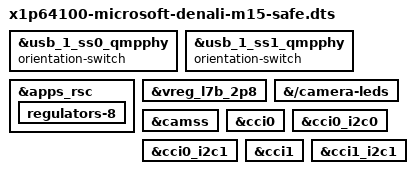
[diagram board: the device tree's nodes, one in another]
// SPDX-License-Identifier: BSD-3-Clause
/*
 * M15 fallback / safe mode (no GPU): complete functional system with
 * audio (speakers with D26 open-loop protection, microphones, DisplayPort audio),
 * cameras (rear OV13858 and front IMX681, RGB only; the unbound IR VD55G0 is
 * excluded from the CAMSS graph), LCD, Wi-Fi, and Bluetooth.
 * GPU disabled (safe from GPU bring-up resets / hangs).
 * Built by the kernel DTB variants script; not a patch, not part of the RPM.
 */
#include "x1p64100-microsoft-denali-m12.dts"
#include "x1-microsoft-denali-audio-d26.dtsi"
#include "x1-microsoft-denali-audio-dp.dtsi"
#include "x1-microsoft-denali-audio-closedloop.dtsi"

/*
 * usb-typec patch 0003 (experiment) deletes `orientation-switch` from both QMP combo PHYs in the PACKAGED board DT.
 * Only the main m15 variant carries it: USB-C DisplayPort is the recovery display, so this fallback keeps the
 * old behaviour (both PHYs registered as orientation switches).
 */
&usb_1_ss0_qmpphy {
	orientation-switch;
};

&usb_1_ss1_qmpphy {
	orientation-switch;
};

&apps_rsc {
	regulators-8 {
		status = "okay";
	};
};

&vreg_l7b_2p8 {
	status = "okay";
};

&{/camera-leds} {
	status = "okay";
};

&camss {
	status = "okay";
};

&cci0 {
	status = "okay";
};

&cci0_i2c0 {
	status = "okay";
};

&cci0_i2c1 {
	status = "okay";
};

&cci1 {
	status = "okay";
};

&cci1_i2c1 {
	status = "okay";
};

/*
 * M16.4 (cameras 0022): CAMSS enumerates every described endpoint before completing registration.
 * The IR sensor VD55G0 has no usable driver, so it never binds and the notifier leaves both RGB
 * sensors with zero media links. Drop the IR endpoint from CAMSS, disable its node and its CCI0
 * bus 0; the rear OV13858 (CCI0 bus 1) and front IMX681 (CCI1 bus 1) stay enabled.
 */
#include "x1-microsoft-denali-camera-no-ir.dtsi"
